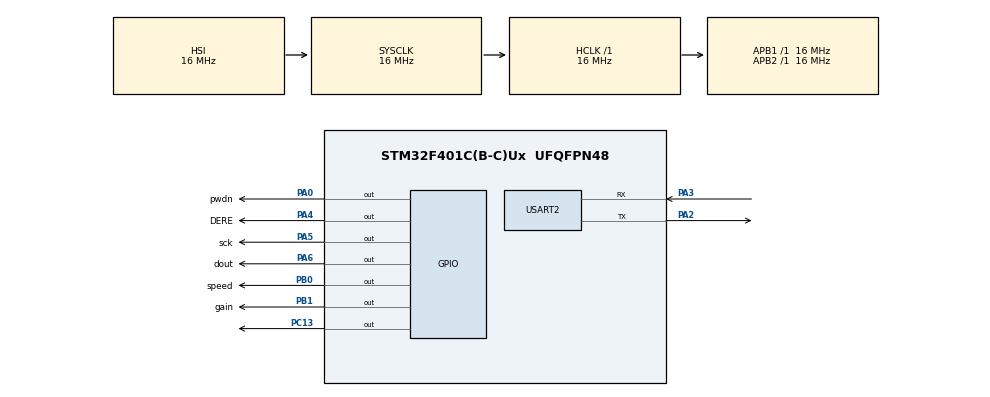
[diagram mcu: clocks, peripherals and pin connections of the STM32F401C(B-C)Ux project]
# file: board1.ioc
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Mcu.Family=STM32F4
Mcu.Name=STM32F401C(B-C)Ux
Mcu.Package=UFQFPN48
NVIC.PriorityGroup=NVIC_PRIORITYGROUP_4
PA0-WKUP.GPIO_Label=pwdn
PA0-WKUP.Signal=GPIO_Output
PA11.Signal=USART6_TX
PA13.Mode=Serial_Wire
PA13.Signal=SYS_JTMS-SWDIO
PA14.Mode=Serial_Wire
PA14.Signal=SYS_JTCK-SWCLK
PA2.Mode=Asynchronous
PA2.Signal=USART2_TX
PA3.Mode=Asynchronous
PA3.Signal=USART2_RX
PA4.GPIO_Label=DERE
PA4.Signal=GPIO_Output
PA5.GPIO_Label=sck
PA5.Signal=GPIO_Output
PA6.GPIO_Label=dout
PA6.Signal=GPIO_Output
PB0.GPIO_Label=speed
PB0.Signal=GPIO_Output
PB1.GPIO_Label=gain
PB1.Signal=GPIO_Output
PC13-ANTI_TAMP.Signal=GPIO_Output
ProjectManager.HeapSize=0x200
ProjectManager.StackSize=0x400
ProjectManager.TargetToolchain=STM32CubeIDE
RCC.AHBFreq_Value=16000000
RCC.APB1Freq_Value=16000000
RCC.APB2Freq_Value=16000000
RCC.CortexFreq_Value=16000000
RCC.HSE_VALUE=25000000
RCC.HSI_VALUE=16000000
RCC.LSE_VALUE=32768
RCC.SYSCLKFreq_VALUE=16000000
RCC.VCOOutputFreq_Value=192000000
USART2.VirtualMode=VM_ASYNC
board=custom

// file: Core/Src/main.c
/* USER CODE BEGIN Header */
/**
  ******************************************************************************
  * @file           : main.c
  * @brief          : Main program body
  ******************************************************************************
  * @attention
  *
  * Copyright (c) 2025 STMicroelectronics.
  * All rights reserved.
  *
  * This software is licensed under terms that can be found in the LICENSE file
  * in the root directory of this software component.
  * If no LICENSE file comes with this software, it is provided AS-IS.
  *
  ******************************************************************************
  */
/* USER CODE END Header */
#include "main.h"

/* USER CODE BEGIN Includes */
#include "ADS1232.h"
#include <stdio.h>
//#include"tinyprintf.h"
#include <string.h>
#include "max232.h"
/* USER CODE END Includes */

/* USER CODE BEGIN PTD */
UART_HandleTypeDef huart2;
/* USER CODE END PTD */

UART_HandleTypeDef huart2;

void SystemClock_Config(void);
static void MX_GPIO_Init(void);
static void MX_USART2_UART_Init(void);

/* USER CODE BEGIN 0 */
#define MY_ADDR 2
char RxBuffer[16];
char TxBuffer[64];
/* USER CODE END 0 */

volatile char buf[64];
int i=0;
const float NO_LOAD_UNITS = 777605.188f;
const float ONE_KG_UNITS  = 833276.875f;
const float KG_PER_UNIT   = 1.00f / (ONE_KG_UNITS - NO_LOAD_UNITS);
//MX485_HandleTypeDef hRs485;

int main(void)
{
  HAL_Init();
  SystemClock_Config();
  MX_GPIO_Init();
  MX_USART2_UART_Init();

//  MX485_Init(&hRs485, &huart2, GPIOA, GPIO_PIN_8);
  ADS1232 adc;
  ADS1232_Init(
    &adc,
    GPIOA, dout_Pin,
    GPIOA, sck_Pin,
    GPIOA, pwdn_Pin,
    GPIOB, speed_Pin,
    GPIOB, gain_Pin,
    SLOW
  );
  adc.SCALE = 1.0f;
//  HAL_GPIO_WritePin(GPIOB, speed_Pin, GPIO_PIN_RESET);
  HAL_GPIO_WritePin(GPIOB, gain_Pin, GPIO_PIN_SET);
//  HAL_GPIO_WritePin(GPIOA, control_Pin, GPIO_PIN_SET);

  float units;
//  float weight=0;
//  char buf[64];
  int idx;
  float weight_kg;

  while (1)
  {
//	  int len = sprintf(buf, "HELLO123\r\n");

	  if(ADS1232_IsReady(&adc)){
		  ADS1232_GetUnits(&adc, &units, 10, 0);
		  i++;
		  units = -units;
		  float delta = units - NO_LOAD_UNITS;
		  weight_kg = (delta * KG_PER_UNIT);
		  if(weight_kg<0)weight_kg=0.0f;
  }
	  uint8_t c;
	  memset(RxBuffer, 0, sizeof(RxBuffer));
	  idx = 0;
	  int pdx=-1;
	  int flg=0;
	  while (HAL_UART_Receive(&huart2, &c, 1, HAL_MAX_DELAY) == HAL_OK) {

		  if(flg==1 ||c =='='){

			  if(pdx>=0)RxBuffer[pdx] = c;
			  pdx++;
			  flg=1;
		  }
		  idx++;
	      if (c == '\n' || idx >= sizeof(RxBuffer) - 1) break;
	  }
	  RxBuffer[idx] = '\0';

	  if (strncmp(RxBuffer, "REQ:", 4) == 0) {

	      int reqAddr = RxBuffer[4] - '0';
	      if (reqAddr == MY_ADDR) {
	          HAL_GPIO_TogglePin(GPIOC, GPIO_PIN_13);
	          HAL_GPIO_WritePin(GPIOA, control_Pin, GPIO_PIN_SET);
//	          weight_kg=22.11f;
	          int txLen = snprintf(TxBuffer, sizeof(TxBuffer), "%+7.5f\n", weight_kg);
	          TxBuffer[txLen]='\n';
	          HAL_UART_Transmit(&huart2, TxBuffer, txLen, 1000);
//	          while (__HAL_UART_GET_FLAG(&huart2, UART_FLAG_TC) == RESET) {}
	          HAL_GPIO_WritePin(GPIOA, control_Pin, GPIO_PIN_RESET);
	      }
	  }

	  HAL_Delay(100);
  }
}

void SystemClock_Config(void)
{
  RCC_OscInitTypeDef RCC_OscInitStruct = {0};
  RCC_ClkInitTypeDef RCC_ClkInitStruct = {0};

  /** Configure the main internal regulator output voltage
  */
  __HAL_RCC_PWR_CLK_ENABLE();
  __HAL_PWR_VOLTAGESCALING_CONFIG(PWR_REGULATOR_VOLTAGE_SCALE2);

  /** Initializes the RCC Oscillators according to the specified parameters
  * in the RCC_OscInitTypeDef structure.
  */
  RCC_OscInitStruct.OscillatorType = RCC_OSCILLATORTYPE_HSI;
  RCC_OscInitStruct.HSIState = RCC_HSI_ON;
  RCC_OscInitStruct.HSICalibrationValue = RCC_HSICALIBRATION_DEFAULT;
  RCC_OscInitStruct.PLL.PLLState = RCC_PLL_NONE;
  if (HAL_RCC_OscConfig(&RCC_OscInitStruct) != HAL_OK)
  {
    Error_Handler();
  }

  /** Initializes the CPU, AHB and APB buses clocks
  */
  RCC_ClkInitStruct.ClockType = RCC_CLOCKTYPE_HCLK|RCC_CLOCKTYPE_SYSCLK
                              |RCC_CLOCKTYPE_PCLK1|RCC_CLOCKTYPE_PCLK2;
  RCC_ClkInitStruct.SYSCLKSource = RCC_SYSCLKSOURCE_HSI;
  RCC_ClkInitStruct.AHBCLKDivider = RCC_SYSCLK_DIV1;
  RCC_ClkInitStruct.APB1CLKDivider = RCC_HCLK_DIV1;
  RCC_ClkInitStruct.APB2CLKDivider = RCC_HCLK_DIV1;

  if (HAL_RCC_ClockConfig(&RCC_ClkInitStruct, FLASH_LATENCY_0) != HAL_OK)
  {
    Error_Handler();
  }
}

static void MX_USART2_UART_Init(void)
{

  huart2.Instance = USART2;
  huart2.Init.BaudRate = 9600;
  huart2.Init.WordLength = UART_WORDLENGTH_8B;
  huart2.Init.StopBits = UART_STOPBITS_1;
  huart2.Init.Parity = UART_PARITY_NONE;
  huart2.Init.Mode = UART_MODE_TX_RX;
  huart2.Init.HwFlowCtl = UART_HWCONTROL_NONE;
  huart2.Init.OverSampling = UART_OVERSAMPLING_16;
  if (HAL_UART_Init(&huart2) != HAL_OK)
  {
    Error_Handler();
  }

}

static void MX_GPIO_Init(void)
{
  GPIO_InitTypeDef GPIO_InitStruct = {0};

  /* GPIO Ports Clock Enable */
  __HAL_RCC_GPIOC_CLK_ENABLE();
  __HAL_RCC_GPIOA_CLK_ENABLE();
  __HAL_RCC_GPIOB_CLK_ENABLE();

  /*Configure GPIO pin Output Level */
  HAL_GPIO_WritePin(GPIOC, GPIO_PIN_13, GPIO_PIN_RESET);

  /*Configure GPIO pin Output Level */
  HAL_GPIO_WritePin(GPIOA, pwdn_Pin|sck_Pin|dout_Pin|control_Pin, GPIO_PIN_RESET);

  /*Configure GPIO pin Output Level */
  HAL_GPIO_WritePin(GPIOB, speed_Pin|gain_Pin, GPIO_PIN_RESET);

  /*Configure GPIO pin : PC13 */
  GPIO_InitStruct.Pin = GPIO_PIN_13;
  GPIO_InitStruct.Mode = GPIO_MODE_OUTPUT_PP;
  GPIO_InitStruct.Pull = GPIO_NOPULL;
  GPIO_InitStruct.Speed = GPIO_SPEED_FREQ_LOW;
  HAL_GPIO_Init(GPIOC, &GPIO_InitStruct);

  /*Configure GPIO pins : pwdn_Pin sck_Pin dout_Pin control_Pin */
  GPIO_InitStruct.Pin = pwdn_Pin|sck_Pin|dout_Pin|control_Pin;
  GPIO_InitStruct.Mode = GPIO_MODE_OUTPUT_PP;
  GPIO_InitStruct.Pull = GPIO_NOPULL;
  GPIO_InitStruct.Speed = GPIO_SPEED_FREQ_LOW;
  HAL_GPIO_Init(GPIOA, &GPIO_InitStruct);

  /*Configure GPIO pins : speed_Pin gain_Pin */
  GPIO_InitStruct.Pin = speed_Pin|gain_Pin;
  GPIO_InitStruct.Mode = GPIO_MODE_OUTPUT_PP;
  GPIO_InitStruct.Pull = GPIO_NOPULL;
  GPIO_InitStruct.Speed = GPIO_SPEED_FREQ_LOW;
  HAL_GPIO_Init(GPIOB, &GPIO_InitStruct);

}

void Error_Handler(void)
{
  /* USER CODE BEGIN Error_Handler_Debug */
  /* User can add his own implementation to report the HAL error return state */
  __disable_irq();
//  while (1)
//  {
//  }
  /* USER CODE END Error_Handler_Debug */
}
